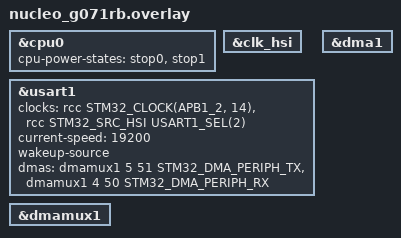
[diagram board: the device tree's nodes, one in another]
/*
 * Copyright The Zephyr Project Contributors
 *
 * SPDX-License-Identifier: Apache-2.0
 */

#include <zephyr/dt-bindings/dma/stm32_dma.h>

&cpu0 {
	cpu-power-states = <&stop0 &stop1>;
};

&clk_hsi {
	status = "okay";
};

dut: &usart1 {
	/* Connect PC4 (TX) to PC5 (RX). */
	clocks = <&rcc STM32_CLOCK(APB1_2, 14)>,
		 <&rcc STM32_SRC_HSI USART1_SEL(2)>;
	current-speed = <19200>;
	wakeup-source;
	dmas = <&dmamux1 5 51 STM32_DMA_PERIPH_TX>,
	       <&dmamux1 4 50 STM32_DMA_PERIPH_RX>;
	dma-names = "tx", "rx";
};

&dma1 {
	status = "okay";
};

&dmamux1 {
	status = "okay";
};
